# R7FA0E107 register map
Vendor: Renesas Electronics Corporation; Series: RA0; File version: 1.10.00
CPU: CM23 r1p0, little endian, no MPU, no FPU, VTOR, 2 interrupt priority bits, 64 interrupts
Registers are 16-bit, read-write, reset 0x0 unless marked. A register's access mark holds for its fields unless they carry their own. Offsets are from the block's base; [hi:lo] are bit positions; {n}, {i} and the like mark numbered series.

## IICA — Serial Interface IICA
Base 0x400A3000
0x00 IICA0 8-bit — IICA Shift Register 0
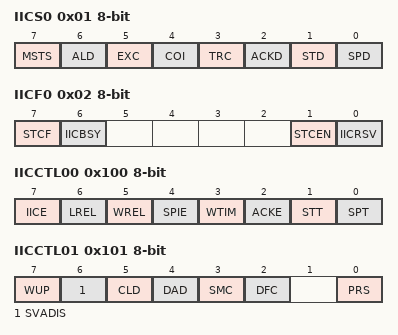
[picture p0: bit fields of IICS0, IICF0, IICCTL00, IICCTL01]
0x01 IICS0 8-bit ro — IICA Status Register 0
  [7] MSTS — Master Status Check Flag
  [6] ALD — Detection of Arbitration Loss
  [5] EXC — Detection of Extension Code Reception
  [4] COI — Detection of Matching Addresses
  [3] TRC — Detection of Transmit and Receive Status
  [2] ACKD — Detection of Acknowledge (ACK)
  [1] STD — Detection of Start Condition
  [0] SPD — Detection of Stop Condition
0x02 IICF0 8-bit — IICA Flag Register 0
  [7] STCF ro — IICCTL00.STT Clear Flag
  [6] IICBSY ro — I2C Bus Status Flag
  [1] STCEN — Initial Start Enable Trigger
  [0] IICRSV — Communication Reservation Function Disable Bit
0x100 IICCTL00 8-bit — IICA Control Register 00
  [7] IICE — I2C Operation Enable
  [6] LREL — Exit from Communications
  [5] WREL — Release from the Clock Stretch State
  [4] SPIE — Enable and Disable Generation of Interrupt Request when Stop Condition is Detected
  [3] WTIM — Control of Clock Stretching and Interrupt Request Generation
  [2] ACKE — Acknowledgment Control
  [1] STT — Start Condition Trigger
  [0] SPT — Stop Condition Trigger
0x101 IICCTL01 8-bit — IICA Control Register 01
  [7] WUP — Control of Address Match Wakeup
  [6] SVADIS — Address Match Disabling Flag
  [5] CLD ro — Detection of SCLA0 Pin Level (Valid Only when IICCTL00.IICE = 1)
  [4] DAD ro — Detection of SDAA0 Pin Level (Valid Only when IICCTL00.IICE = 1)
  [3] SMC — Operation Mode Switching
  [2] DFC — Digital Filter Operation Control
  [0] PRS — IICA Operation Clock (fMCK)
0x102 IICWL0 8-bit reset 0xFF — IICA Low,level Width Setting Register 0
0x103 IICWH0 8-bit reset 0xFF — IICA High,level Width Setting Register 0
0x104 SVA0 8-bit — Slave Address Register 0
  [7:1] A — 7-bit Local Address when in Slave Mode of Unit 0

## UARTA — Serial Interface UARTA
Base 0x400A3400
0x00 TXBA0 8-bit reset 0xFF — Transmit Buffer Register 0
0x01 RXBA0 8-bit ro reset 0xFF — Receive Buffer Register 0
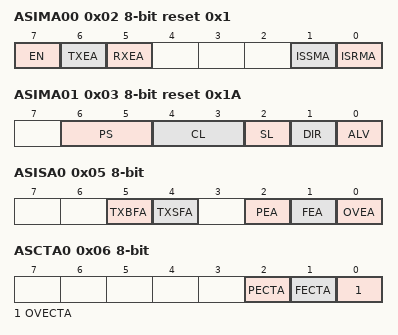
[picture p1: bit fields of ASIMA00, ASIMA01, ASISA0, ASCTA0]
0x02 ASIMA00 8-bit reset 0x1 — Operation Mode Setting Register 00
  [7] EN — UART Operation Enable
  [6] TXEA — Transmission Enable
  [5] RXEA — Reception Enable
  [1] ISSMA — Transmit Interrupt Mode Select
  [0] ISRMA — Receive Interrupt Mode Select
0x03 ASIMA01 8-bit reset 0x1A — Operation Mode Setting Register 01
  [6:5] PS — Transmission and Reception Parity Bit Setting
  [4:3] CL — Transmission and Reception Character Length Setting
  [2] SL — Transmission Stop Bit Length Setting
  [1] DIR — Transmission and Reception Order Setting
  [0] ALV — Transmission and Reception Level Setting
0x04 BRGCA0 8-bit reset 0xFF — Baud Rate Generator Control Register 0
0x05 ASISA0 8-bit ro — Status Register 0
  [5] TXBFA — Transmit Buffer Data Flag
  [4] TXSFA — Transmit Shift Register Data Flag
  [2] PEA — Parity Error Flag
  [1] FEA — Framing Error Flag
  [0] OVEA — Overrun Error Flag
0x06 ASCTA0 8-bit — Status Clear Trigger Register 0
  [2] PECTA — Parity Error Flag Clear Trigger
  [1] FECTA — Framing Error Flag Clear Trigger
  [0] OVECTA — Overrun Error Flag Clear Trigger
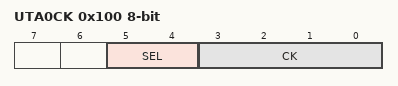
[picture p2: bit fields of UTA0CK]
0x100 UTA0CK 8-bit — UARTA Clock Select Register 0
  [5:4] SEL — fSEL Clock Select
  [3:0] CK — UARTA0 Operation Clock Select (fUTA0)

## TML32 — 32-bit Interval Timer
Base 0x400A3800
{0x0+2i} ITLCMP0{i} (i=0..1) reset 0xFFFF — Interval Timer Compare Registers 0{i}
{0x0+2i} ITLCMP0{i}_L (i=0..1) 8-bit reset 0xFF (alternate view of ITLCMP0{i}) — Interval Timer Compare Registers 0{i}
{0x1+2i} ITLCMP0{i}_H (i=0..1) 8-bit reset 0xFF (alternate view of ITLCMP0{i}) — Interval Timer Compare Registers 0{i}
0x04 ITLCAP00 ro — Interval Timer Capture Register 00
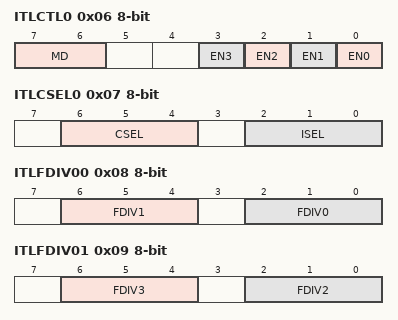
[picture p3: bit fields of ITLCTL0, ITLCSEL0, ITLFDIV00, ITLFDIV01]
0x06 ITLCTL0 8-bit — Interval Timer Control Register
  [7:6] MD — Selection of 8-bit, 16-bit, or 32-bit Counter Mode
  [3] EN3 — 8-bit Counter Mode: ITL013 Count Enable
  [2] EN2 — 8-bit Counter Mode: ITL012 Count Enable
  [1] EN1 — 8-bit Counter Mode: ITL001 Count Enable
  [0] EN0 — 8-bit Counter Mode: ITL000 Count Enable
0x07 ITLCSEL0 8-bit — Interval Timer Clock Select Register 0
  [6:4] CSEL — Selection of Interval Timer Count Clock for Capturing (fITL1)
  [2:0] ISEL — Selection of Interval Timer Count Clock (fITL0)
0x08 ITLFDIV00 8-bit — Interval Timer Frequency Division Register 0
  [6:4] FDIV1 — 8-bit Counter Mode: Counter Clock for ITL001
  [2:0] FDIV0 — 8-bit Counter Mode: Counter Clock for ITL000
0x09 ITLFDIV01 8-bit — Interval Timer Frequency Division Register 1
  [6:4] FDIV3 — 8-bit Counter Mode: Counter Clock for ITL013
  [2:0] FDIV2 — 8-bit Counter Mode: Counter Clock for ITL012
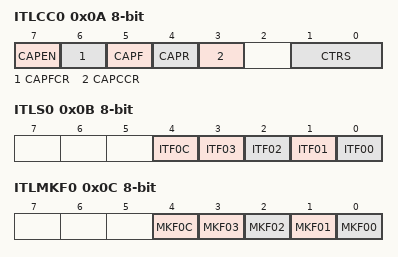
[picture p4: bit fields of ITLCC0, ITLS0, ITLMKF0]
0x0A ITLCC0 8-bit — Interval Timer Capture Control Register 0
  [7] CAPEN — Capture Enable
  [6] CAPFCR — Capture Completion Flag Clear
  [5] CAPF ro — Capture Completion Flag
  [4] CAPR — Software Capture Trigger
  [3] CAPCCR — Selection of Capture Counter Clearing After Capturing
  [1:0] CTRS — Selection of Capture Trigger
0x0B ITLS0 8-bit — Interval Timer Status Register
  [4] ITF0C — Capture Detection Flag
  [n] ITF{n:02} (n=0..3) — Compare Match Detection Flag for Channel {n}
0x0C ITLMKF0 8-bit — Interval Timer Match Detection Mask Register
  [4] MKF0C — Mask for Capture Detection Status Flag
  [n] MKF{n:02} (n=0..3) — Mask for Compare Match Status Flag for Channel {n}
